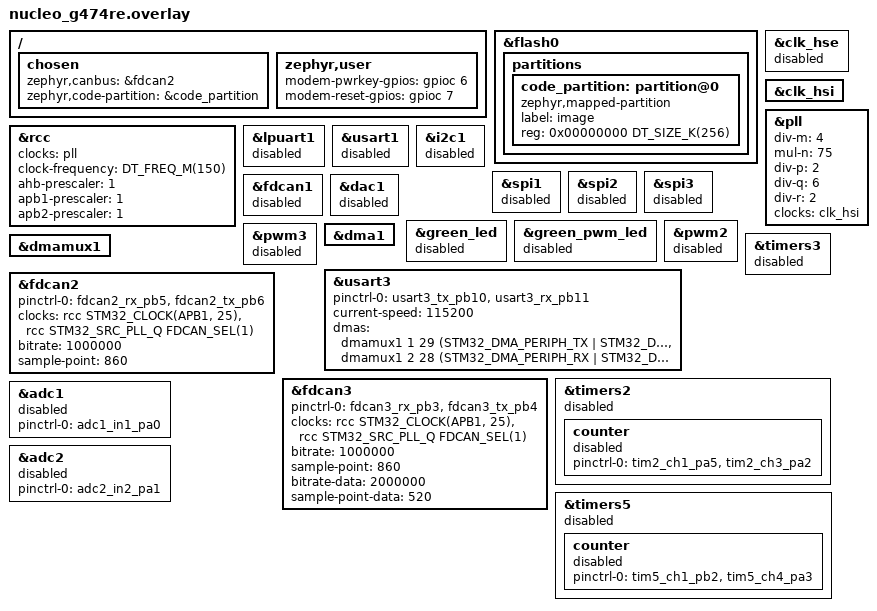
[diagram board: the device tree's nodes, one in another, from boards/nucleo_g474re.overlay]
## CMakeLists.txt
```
cmake_minimum_required(VERSION 3.20.0)

find_package(Zephyr REQUIRED HINTS $ENV{ZEPHYR_BASE})
project(telemetry27)

target_sources(app PRIVATE
	src/main.c
	src/platform.c
	src/telemetry.c
	src/telemetry_buffer.c
	src/telemetry_pack.c
	src/can_decode.c
	src/can_bus.c
	src/modem_fsm.c
	src/modem_at.c
	src/modem_parser.c
	src/modem_uart.c
	src/modem_power.c
)

target_sources_ifdef(CONFIG_TELEMETRY_SIM app PRIVATE
	src/modem_port_sim.c
	src/sim_vehicle.c
)

target_sources_ifndef(CONFIG_TELEMETRY_SIM app PRIVATE
	src/modem_port_hw.c
)
```

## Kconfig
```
# SPDX-License-Identifier: Apache-2.0

mainmenu "Telemetry27"

menu "Telemetry application"

config TELEMETRY_SIM
	bool "Host simulation of CAN frames and Quectel AT replies"
	default y if BOARD_NATIVE_SIM || BOARD_QEMU_CORTEX_M3
	help
	  Build without STM32 peripherals. A thread injects BMS 0x060 and
	  inverter 0x0B0 frames, and the modem port answers AT commands
	  with OK, the QISEND prompt and SEND OK.

endmenu

source "Kconfig.zephyr"
```

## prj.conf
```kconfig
CONFIG_LOG=y
CONFIG_LOG_DEFAULT_LEVEL=3
CONFIG_REBOOT=y

# ring_buf her zaman derlenir. CONFIG_RING_BUFFER Zephyr 4.4'te eski
# claim/finish API'sini geri getiren, kaldirilacak bir anahtardir.
```

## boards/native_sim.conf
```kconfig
CONFIG_LOG_MODE_IMMEDIATE=y
```

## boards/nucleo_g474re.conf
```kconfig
CONFIG_USE_DT_CODE_PARTITION=y

CONFIG_UART_CONSOLE=n
CONFIG_USE_SEGGER_RTT=y
CONFIG_RTT_CONSOLE=y
CONFIG_LOG_BACKEND_RTT=y
CONFIG_LOG_BACKEND_RTT_MODE_DROP=y

CONFIG_GPIO=y
CONFIG_SERIAL=y
CONFIG_UART_INTERRUPT_DRIVEN=y
CONFIG_UART_ASYNC_API=y

CONFIG_CAN=y
CONFIG_CAN_FD_MODE=y
CONFIG_CAN_DEFAULT_BITRATE=1000000
CONFIG_CAN_DEFAULT_BITRATE_DATA=2000000
```

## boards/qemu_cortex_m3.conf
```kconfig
CONFIG_TELEMETRY_SIM=y
CONFIG_LOG_MODE_IMMEDIATE=y
CONFIG_QEMU_EXTRA_FLAGS="-semihosting"
```

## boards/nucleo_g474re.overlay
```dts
/*
 * Telemetry27 pin haritasi.
 *
 * Derleme hedefi nucleo_g474re: Zephyr'de hazir olan en yakin kart.
 * Asil MCU STM32G474RCT6 (256 KB flash). Nucleo'daki G474RET6 512 KB'dir.
 * Asagidaki kod bolumu 256 KB'a sabitlenir ki imaj gercek karta da sigsin
 * ve 0x08000000'dan baslasin. Nucleo tanimi aksi halde uygulamayi MCUboot
 * slotuna (0x0800C000) yerlestirir; bootloader olmadan islemci oradan acilmaz.
 *
 * Saat, calisan Cube firmware ile ayni: HSI 16 MHz / 4 * 75, PLLR /2 = 150 MHz.
 * FDCAN cekirdegi PLLQ /6 = 50 MHz. .ioc PF0/PF1'i HSE gosterir; SystemClock_Config
 * HSE'yi acmaz. Nucleo'nun 24 MHz HSE'si bu kartta yok, o yuzden kapali.
 */

#include <zephyr/dt-bindings/dma/stm32_dma.h>

/ {
	chosen {
		zephyr,canbus = &fdcan2;
		zephyr,code-partition = &code_partition;
	};

	zephyr,user {
		modem-pwrkey-gpios = <&gpioc 6 GPIO_ACTIVE_HIGH>;
		modem-reset-gpios = <&gpioc 7 GPIO_ACTIVE_HIGH>;
	};
};

/delete-node/ &boot_partition;
/delete-node/ &slot0_partition;
/delete-node/ &slot1_partition;
/delete-node/ &storage_partition;

&flash0 {
	partitions {
		code_partition: partition@0 {
			compatible = "zephyr,mapped-partition";
			label = "image";
			reg = <0x00000000 DT_SIZE_K(256)>;
		};
	};
};

&clk_hse {
	status = "disabled";
};

&clk_hsi {
	status = "okay";
};

&pll {
	div-m = <4>;
	mul-n = <75>;
	div-p = <2>;
	div-q = <6>;
	div-r = <2>;
	clocks = <&clk_hsi>;
	status = "okay";
};

&rcc {
	clocks = <&pll>;
	clock-frequency = <DT_FREQ_M(150)>;
	ahb-prescaler = <1>;
	apb1-prescaler = <1>;
	apb2-prescaler = <1>;
};

/* Nucleo varsayilanlari bizim pinleri kaplar. Hepsini birakiyoruz. */
&lpuart1 {
	status = "disabled"; /* PA2, PA3: TIM, ST-Link konsolu degil */
};

&usart1 {
	status = "disabled";
};

&i2c1 {
	status = "disabled";
};

&spi1 {
	status = "disabled"; /* PA5: tekerlek TIM2_CH1, Nucleo LED/SPI degil */
};

&spi2 {
	status = "disabled";
};

&spi3 {
	status = "disabled";
};

&fdcan1 {
	status = "disabled"; /* PA11/PA12 bu kartta USB, CAN1 degil */
};

&dac1 {
	status = "disabled";
};

&green_led {
	status = "disabled"; /* PA5 */
};

&green_pwm_led {
	status = "disabled";
};

&pwm2 {
	status = "disabled"; /* tim2_ch1_pa5 */
};

&pwm3 {
	status = "disabled"; /* tim3_ch1_pb4 = bizim FDCAN3_TX */
};

&timers3 {
	status = "disabled";
};

/*
 * USART3, Quectel AT portu. PB10 TX, PB11 RX, 115200 8N1.
 * DMA kanallari Cube ile ayni: Channel1 TX (istek 29), Channel2 RX (istek 28).
 * Zephyr G4'te kanal numarasi 1'den baslar. RX dairesel; TX normal.
 */
&dma1 {
	status = "okay";
};

&dmamux1 {
	status = "okay";
};

&usart3 {
	pinctrl-0 = <&usart3_tx_pb10 &usart3_rx_pb11>;
	pinctrl-names = "default";
	current-speed = <115200>;
	dmas = <&dmamux1 1 29 (STM32_DMA_PERIPH_TX | STM32_DMA_PRIORITY_LOW)>,
	       <&dmamux1 2 28 (STM32_DMA_PERIPH_RX | STM32_DMA_PRIORITY_HIGH |
			       STM32_DMA_MODE_CYCLIC)>;
	dma-names = "tx", "rx";
	status = "okay";
};

/*
 * FDCAN saat kaynagi PLLQ (FDCAN_SEL 1). 50 MHz, prescaler 1.
 * Klasik 1 Mbit: 1+42+7 tq, ornek noktasi 860/1000.
 * FD data 2 Mbit: 1+12+12 tq, ornek noktasi 520/1000.
 * Zephyr seg1/seg2'yi bu ornek noktasindan kendisi secer.
 */
&fdcan2 {
	pinctrl-0 = <&fdcan2_rx_pb5 &fdcan2_tx_pb6>;
	pinctrl-names = "default";
	clocks = <&rcc STM32_CLOCK(APB1, 25)>,
		 <&rcc STM32_SRC_PLL_Q FDCAN_SEL(1)>;
	bitrate = <1000000>;
	sample-point = <860>;
	status = "okay";
};

&fdcan3 {
	pinctrl-0 = <&fdcan3_rx_pb3 &fdcan3_tx_pb4>;
	pinctrl-names = "default";
	clocks = <&rcc STM32_CLOCK(APB1, 25)>,
		 <&rcc STM32_SRC_PLL_Q FDCAN_SEL(1)>;
	bitrate = <1000000>;
	sample-point = <860>;
	bitrate-data = <2000000>;
	sample-point-data = <520>;
	status = "okay";
};

/* Tekerlek input-capture. Uygulama henuz okumuyor; pinler kayitli, surucu kapali. */
&timers2 {
	status = "disabled";

	counter {
		pinctrl-0 = <&tim2_ch1_pa5 &tim2_ch3_pa2>;
		pinctrl-names = "default";
		status = "disabled";
	};
};

&timers5 {
	status = "disabled";

	counter {
		pinctrl-0 = <&tim5_ch1_pb2 &tim5_ch4_pa3>;
		pinctrl-names = "default";
		status = "disabled";
	};
};

/*
 * ADC1 PA0 ve ADC2 PA1 Cube'da acik, App/ okumuyor.
 * Zephyr G4 dtsi su an iki ADC'yi ayni anda desteklemiyor; ikisi de kapali.
 */
&adc1 {
	pinctrl-0 = <&adc1_in1_pa0>;
	pinctrl-names = "default";
	status = "disabled";
};

&adc2 {
	pinctrl-0 = <&adc2_in2_pa1>;
	pinctrl-names = "default";
	status = "disabled";
};
```

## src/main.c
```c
#include <zephyr/kernel.h>
#include <zephyr/logging/log.h>

LOG_MODULE_REGISTER(app, LOG_LEVEL_INF);

int main(void)
{
	LOG_INF("Telemetry27 Zephyr");
#if IS_ENABLED(CONFIG_TELEMETRY_SIM)
	LOG_INF("endurance sim: 30 dk, 18000 paket");
#else
	LOG_INF("hedef STM32G474, USART3 / FDCAN2 / FDCAN3");
#endif
	return 0;
}
```

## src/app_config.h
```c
#ifndef APP_CONFIG_H_
#define APP_CONFIG_H_

/* Network */
#define APP_UDP_HOST              "135.125.196.63"
#define APP_UDP_PORT              5010
#define APP_APN                   "internet"

/* Pack rate: 10 Hz for vehicle/site trial; flip APP_TELEMETRY_10HZ to 0
 * for the proven 2 Hz (500 ms) TX-safe bench/vehicle fallback. */
#define APP_TELEMETRY_10HZ            1
#if APP_TELEMETRY_10HZ
#define APP_TELEMETRY_PERIOD_MS       100u   /* 10 Hz — Final26 vehicle rate */
#else
#define APP_TELEMETRY_PERIOD_MS       500u   /* 2 Hz — shared-rail / weak PSU */
#endif

/* Modem boot delay before GSM task starts link bring-up */
#define APP_GSM_BOOT_DELAY_MS     3000u

/* Warm flash: 0 = Final26 (AT OK → leave modem on, no QPOWD). 1 = force soft power-down. */
#define APP_MODEM_WARM_FLASH_QPOWD    0

/* RF: off = Quectel default (~23 dBm). Set 1 + 1800 for shared-+5V bench. */
#define APP_MODEM_RF_PROFILE_ENABLE   0
#define APP_MODEM_SARCFG_MAX_POWER    1800u   /* 18.0 dBm when profile on */
#define APP_MODEM_SARCFG_BAND         20u

/* Feature flags */
#define APP_TELEMETRY_LOW_BW_ENABLE   0
/* 0 = vehicle: MainBuffer filled only from CAN decode (no mock overwrite). */
#define APP_TELEMETRY_BENCH_TEST      0
#define APP_MODEM_DEBUG_LOG           1

/* Watchdog / recovery */
#define APP_GSM_SILENCE_WATCHDOG      1
#define APP_GSM_SILENCE_RESET_MS      120000u

#define APP_IWDG_ENABLE_REFRESH       1

#endif /* APP_CONFIG_H_ */
```

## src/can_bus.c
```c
#include "can_bus.h"
#include "can_decode.h"
#include "telemetry_buffer.h"

#include <string.h>
#include <zephyr/kernel.h>
#include <zephyr/logging/log.h>

LOG_MODULE_REGISTER(can_bus, LOG_LEVEL_INF);

struct can_rx_msg {
	uint8_t bus;
	uint8_t len;
	uint16_t pad;
	uint32_t id;
	uint8_t data[64];
};

K_MSGQ_DEFINE(can_rx_q, sizeof(struct can_rx_msg), 24, 4);

void can_rx_submit(uint8_t bus, uint32_t id, const uint8_t *data, uint8_t len)
{
	struct can_rx_msg msg;

	memset(&msg, 0, sizeof(msg));
	msg.bus = bus;
	msg.id = id;
	msg.len = len > sizeof(msg.data) ? (uint8_t)sizeof(msg.data) : len;
	if (data != NULL && msg.len > 0u) {
		memcpy(msg.data, data, msg.len);
	}
	if (k_msgq_put(&can_rx_q, &msg, K_NO_WAIT) != 0) {
		evt_overflow_cnt++;
	}
}

#if !IS_ENABLED(CONFIG_TELEMETRY_SIM)

#include <zephyr/device.h>
#include <zephyr/drivers/can.h>

static const struct device *const can_classic = DEVICE_DT_GET(DT_NODELABEL(fdcan2));
static const struct device *const can_fd = DEVICE_DT_GET(DT_NODELABEL(fdcan3));

static void can_rx_cb(const struct device *dev, struct can_frame *frame, void *user)
{
	uint8_t len;

	ARG_UNUSED(dev);
	len = can_dlc_to_bytes(frame->dlc);
	can_rx_submit((uint8_t)(uintptr_t)user, frame->id, frame->data, len);
}

static int add_accept_all(const struct device *dev, uintptr_t bus)
{
	const struct can_filter std = {
		.id = 0u,
		.mask = 0u,
		.flags = 0u,
	};
	const struct can_filter ext = {
		.id = 0u,
		.mask = 0u,
		.flags = CAN_FILTER_IDE,
	};
	int id;

	id = can_add_rx_filter(dev, can_rx_cb, (void *)bus, &std);
	if (id < 0) {
		LOG_ERR("std filtre %d", id);
		return id;
	}
	id = can_add_rx_filter(dev, can_rx_cb, (void *)bus, &ext);
	if (id < 0) {
		LOG_WRN("ext filtre %d", id);
	}
	return 0;
}

static int start_controller(const struct device *dev, uintptr_t bus, const char *name)
{
	int rc;

	if (!device_is_ready(dev)) {
		LOG_ERR("%s hazir degil", name);
		return -1;
	}
	rc = add_accept_all(dev, bus);
	if (rc != 0) {
		return rc;
	}
	rc = can_start(dev);
	if (rc != 0) {
		LOG_ERR("%s start %d", name, rc);
		return rc;
	}
	LOG_INF("%s dinleniyor", name);
	return 0;
}

static void can_hw_start(void)
{
	(void)start_controller(can_classic, CAN_BUS_CLASSIC, "fdcan2");
	(void)start_controller(can_fd, CAN_BUS_FD, "fdcan3");
}

#else

static void can_hw_start(void)
{
	LOG_INF("CAN donanimi yok, cerceveler sim_vehicle'dan gelecek");
}

#endif

static void can_thread(void *p1, void *p2, void *p3)
{
	ARG_UNUSED(p1);
	ARG_UNUSED(p2);
	ARG_UNUSED(p3);

	can_hw_start();
	while (1) {
		struct can_rx_msg msg;

		if (k_msgq_get(&can_rx_q, &msg, K_FOREVER) != 0) {
			continue;
		}
		telemetry_lock();
		CAN_ProcessRxFrame(msg.bus, msg.id, msg.data, msg.len);
		telemetry_on_can_id(msg.id);
		telemetry_unlock();
	}
}

K_THREAD_DEFINE(can_tid, 2048, can_thread, NULL, NULL, NULL, 4, 0, 0);
```

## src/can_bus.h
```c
#ifndef CAN_BUS_H_
#define CAN_BUS_H_

#include <stdint.h>

void can_rx_submit(uint8_t bus, uint32_t id, const uint8_t *data, uint8_t len);

#endif
```

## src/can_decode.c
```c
/*
 * can_decode.c
 *
 *  Created on: 18 Tem 2026
 *      Author: onury
 */

/*
 * Faz 3: CAN -> MainBuffer decode. Tek giris fonksiyonu (CAN_ProcessRxFrame)
 * her cerceveyi bus + ID'ye gore cozer ve fiziksel degerleri MainBuffer'a yazar.
 *
 * Referans: vcu26_firmware/CM7 decode kodlari (bms.cpp, lvbms.cpp, imu.cpp,
 * GPS.cpp, damper.cpp, brake.cpp, dashboard.cpp, inverter.cpp) ve can_decode.h.
 * Olcek/endianness/bayt-offset degerleri VCU decode ile birebir aynidir.
 *
 * NOT (birim): Telemetry_TransmitFrame her alani kendi olcegiyle paketler
 * (or. f[...]*100 -> i16). Bu yuzden burada FIZIKSEL deger yazilir; VCU'nun
 * ayni fiziksel degeri urettigi dogrulandi. Tek istisna damper: VCU metre
 * uretir ama telemetri paketlemesi *10 oldugundan burada mm saklanir (asagida).
 */

#include "can_decode.h"
#include "telemetry_buffer.h"
#include <string.h>

extern MainBuffer_t MainBuffer;

static uint16_t damper_raw_fl = (uint16_t)DAMPER_REST_FL;
static uint16_t damper_raw_fr = (uint16_t)DAMPER_REST_FR;
static uint16_t damper_raw_rl = (uint16_t)DAMPER_REST_RL;
static uint16_t damper_raw_rr = (uint16_t)DAMPER_REST_RR;

static int16_t inv_dcbus_voltage_scaled = 0; /* V (int16, /10 uygulanmis) */
/* 0x060 geldi → hücre temp/volt delta referansı (min) geçerli (VCU/dash birebir). */
static uint8_t bms_cell_min_valid = 0;
/* 0x256 d4 araç hızı otoritesi (dashboard ile aynı). Yoksa 0x0B0 RPM fallback. */
static uint8_t vcu_speed_from_status = 0;

#define BMS_CELL_V_MIN  2.50f
#define BMS_CELL_V_MAX  4.25f

static uint8_t encode_temp_u8(float temp_c)
{
    float enc = temp_c + 40.0f;
    if (enc < 0.0f)   enc = 0.0f;
    if (enc > 255.0f) enc = 255.0f;
    return (uint8_t)enc;
}

static void diff_checker(const uint8_t *d, uint8_t count)
{
    const float min_v = MainBuffer.f[BMS_MIN_CELL_VOLTAGE_f];
    if (min_v <= 0.0f) {
        return;
    }

    for (uint8_t i = 0; i < count; i++) {
        const float cell_v = min_v + ((float)d[i] / 100.0f);
        if (cell_v < BMS_CELL_V_MIN || cell_v > BMS_CELL_V_MAX) {
            Telemetry_SetError(ERR_BMS_CELL_VOLTAGE);
            return; /* baska bank OK diye temizleme — sticky */
        }
    }
}

int32_t CAN_DecodeRaw(const uint8_t *d, uint8_t start, uint8_t width, bool sgned, bool bigendian){
    uint32_t raw = 0;
    if (bigendian == true) {
        for (uint8_t i = 0; i < width; i++)
            raw = (raw << 8) | d[start + i];          /* d[start] = MSB */
    } else {
        for (uint8_t i = 0; i < width; i++)
            raw |= (uint32_t)d[start + i] << (8 * i);  /* d[start] = LSB */
    }
    if (sgned == true && width < 4){                            /* isaret genisletme */
        uint32_t signbit = 1u << (8 * width - 1);
        if (raw & signbit)
            raw |= ~((1u << (8 * width)) - 1);
    }
    return (int32_t)raw;
}

float CAN_Decode(const uint8_t *d, uint8_t start, uint8_t width, bool sgned, bool bigendian, float scale){
    int32_t raw = CAN_DecodeRaw(d, start, width, sgned, bigendian);
    return (scale != 0.0f) ? (float)raw / scale : (float)raw;
}

static float damper_angle_dev(uint16_t raw, float rest)
{
    float diff = (float)raw - rest;
    while (diff >  DAMPER_RAW_HALF) diff -= DAMPER_RAW_FULL;
    while (diff < -DAMPER_RAW_HALF) diff += DAMPER_RAW_FULL;
    return diff / DAMPER_RAW_PER_DEG;
}

static void damper_recompute(void)
{
    /* kose aci sapmasi (derece) * mirror isareti ("sikisma = +") */
    float devFL = damper_angle_dev(damper_raw_fl, DAMPER_REST_FL) * DAMPER_SIGN_FL;
    float devFR = damper_angle_dev(damper_raw_fr, DAMPER_REST_FR) * DAMPER_SIGN_FR;
    float devRL = damper_angle_dev(damper_raw_rl, DAMPER_REST_RL) * DAMPER_SIGN_RL;
    float devRR = damper_angle_dev(damper_raw_rr, DAMPER_REST_RR) * DAMPER_SIGN_RR;

    /* derece -> mm  (VCU: derece->metre; biz mm sakliyoruz ki TransmitFrame'in
     * *10 paketlemesi cozunurlugu korusun. Motion ratio VCU'da placeholder.) */
    const float k = DAMPER_M_PER_DEG * DAMPER_MM_PER_M; /* mm/derece */
    float zFL = devFL * k, zFR = devFR * k, zRL = devRL * k, zRR = devRR * k;

    /* heave = ortalama dusey hareket, roll = sol-sag farki / 2 (VCU modal ayrisim) */
    MainBuffer.f[DAMPER_COMPRESSION_FH_f] = (zFL + zFR) * 0.5f; /* on heave  (mm) */
    MainBuffer.f[DAMPER_COMPRESSION_FR_f] = (zFL - zFR) * 0.5f; /* on roll   (mm) */
    MainBuffer.f[DAMPER_COMPRESSION_RH_f] = (zRL + zRR) * 0.5f; /* arka heave(mm) */
    MainBuffer.f[DAMPER_COMPRESSION_RR_f] = (zRL - zRR) * 0.5f; /* arka roll (mm) */
    /* per-kose dusey hareket (mm) */
    MainBuffer.f[WHEEL_TRAVEL_FL_f] = zFL;
    MainBuffer.f[WHEEL_TRAVEL_FR_f] = zFR;
    MainBuffer.f[WHEEL_TRAVEL_RL_f] = zRL;
    MainBuffer.f[WHEEL_TRAVEL_RR_f] = zRR;
}

/* ======================= Tek decode/dispatch fonksiyonu ======================= */
void CAN_ProcessRxFrame(uint8_t bus, uint32_t id, const uint8_t *d, uint8_t len)
{
    /* ================= FD hatti (FDCAN3): BMS, LV-BMS, IMU, GPS ================= */
    if (bus == CAN_BUS_FD) {
        switch (id) {

        /* ---- HV BMS ozet (LE, >=30B) — Excel(7) / VCU bms.cpp / dash Decode_BMS_0x60 ---- */
        case CANID_BMS:
            if (len < 30u) break;
            MainBuffer.f[BMS_MAX_CELL_TEMP_f]    = CAN_Decode(d,  0, 2, true,  false, 100.0f);
            MainBuffer.f[BMS_MIN_CELL_TEMP_f]    = CAN_Decode(d,  2, 2, true,  false, 100.0f);
            MainBuffer.f[BMS_AVG_CELL_TEMP_f]    = CAN_Decode(d,  4, 2, true,  false, 100.0f);
            MainBuffer.f[BMS_MAX_SLAVE_TEMP_f]   = CAN_Decode(d,  6, 2, true,  false, 100.0f);
            MainBuffer.f[BMS_MAX_CELL_VOLTAGE_f] = CAN_Decode(d,  8, 2, false, false, 100.0f);
            MainBuffer.f[BMS_MIN_CELL_VOLTAGE_f] = CAN_Decode(d, 10, 2, false, false, 100.0f);
            /* d[12]=maxCellNo, d[13]=minCellNo -> telemetri'de alan yok, atla */
            MainBuffer.f[BMS_AVG_CELL_VOLTAGE_f] = CAN_Decode(d, 14, 2, false, false, 100.0f);
            MainBuffer.f[BMS_TOTAL_VOLTAGE_f]    = CAN_Decode(d, 16, 2, false, false, 100.0f);
            MainBuffer.f[BMS_ESTIMATED_SoC_f]    = CAN_Decode(d, 18, 2, false, false, 10000.0f);
            MainBuffer.u32[BMS_POWER_u32]        = (uint32_t)CAN_DecodeRaw(d, 20, 3, false, false);
            MainBuffer.f[BMS_CURRENT_f]          = CAN_Decode(d, 23, 2, true,  false, 10.0f);
            MainBuffer.u16[BMS_FAULTS_u16]       = (uint16_t)CAN_DecodeRaw(d, 25, 2, false, false);
            /* d[27..28]=leftChargeSec -> telemetri'de alan yok, atla */
            MainBuffer.u8[BMS_CONTRACTORS_u8]    = d[29];
            bms_cell_min_valid = 1u;
            break;

        /* ---- Hucre gerilimleri: her bayt MIN hucreye gore DELTA (ham byte saklanir) ----
         * Sunucu: hucre_V = BMS_MIN_CELL_VOLTAGE + delta/100. cell_voltages[] u8. */
        case CANID_BMS_VOLT1:
            if (!bms_cell_min_valid || len < 32u) break;
            memcpy(&MainBuffer.cell_voltages[0],  d, 32);
            diff_checker(d, 32);
            break;
        case CANID_BMS_VOLT2:
            if (!bms_cell_min_valid || len < 32u) break;
            memcpy(&MainBuffer.cell_voltages[32], d, 32);
            diff_checker(d, 32);
            break;
        case CANID_BMS_VOLT3:
            if (!bms_cell_min_valid || len < 32u) break;
            memcpy(&MainBuffer.cell_voltages[64], d, 32);
            diff_checker(d, 32);
            break;

        /* ---- Hucre sicakliklari: u16 LE delta /100; abs = MIN_CELL_TEMP + delta
         * (VCU bms.cpp + dash Decode_BMS_CellTemps). Paket: °C+40 → u8. ---- */
        case CANID_BMS_TEMP1:
            if (!bms_cell_min_valid || len < 64u) break;
            for (uint8_t i = 0; i < 32; i++) {
                float t = MainBuffer.f[BMS_MIN_CELL_TEMP_f] +
                          CAN_Decode(d, (uint8_t)(i * 2u), 2, false, false, 100.0f);
                MainBuffer.cell_temperatures[i] = encode_temp_u8(t);
            }
            break;

        case CANID_BMS_TEMP2:
            if (!bms_cell_min_valid || len < 64u) break;
            for (uint8_t i = 0; i < 32; i++) {
                float t = MainBuffer.f[BMS_MIN_CELL_TEMP_f] +
                          CAN_Decode(d, (uint8_t)(i * 2u), 2, false, false, 100.0f);
                MainBuffer.cell_temperatures[i + 32] = encode_temp_u8(t);
            }
            break;

        case CANID_BMS_TEMP3:
            if (!bms_cell_min_valid || len < 64u) break;
            for (uint8_t i = 0; i < 32; i++) {
                float t = MainBuffer.f[BMS_MIN_CELL_TEMP_f] +
                          CAN_Decode(d, (uint8_t)(i * 2u), 2, false, false, 100.0f);
                MainBuffer.cell_temperatures[i + 64] = encode_temp_u8(t);
            }
            break;

        /* ---- LV BMS (LE, >=23B) ---- */
        case CANID_LVBMS:
            if (len < 23u) break;
            MainBuffer.f[LVBMS_VOLTAGE_f]          = CAN_Decode(d,  0, 2, false, false, 100.0f);
            MainBuffer.f[LVBMS_CELL_REAL0_f]       = CAN_Decode(d,  2, 2, false, false, 100.0f);
            MainBuffer.f[LVBMS_CELL_REAL1_f]       = CAN_Decode(d,  4, 2, false, false, 100.0f);
            MainBuffer.f[LVBMS_CELL_REAL2_f]       = CAN_Decode(d,  6, 2, false, false, 100.0f);
            MainBuffer.f[LVBMS_CELL_REAL3_f]       = CAN_Decode(d,  8, 2, false, false, 100.0f);
            MainBuffer.f[LVBMS_MAX_CELL_VOLTAGE_f] = CAN_Decode(d, 10, 2, false, false, 100.0f);
            MainBuffer.f[LVBMS_MIN_CELL_VOLTAGE_f] = CAN_Decode(d, 12, 2, false, false, 100.0f);
            MainBuffer.u8[LVBMS_CELL_MIN_NUMBER_u8] = d[14];
            MainBuffer.u8[LVBMS_CELL_MAX_NUMBER_u8] = d[15];
            MainBuffer.f[LVBMS_CURRENT_f]          = CAN_Decode(d, 16, 2, true,  false, 10.0f);
            MainBuffer.f[LVBMS_MAX_TEMP_f]         = CAN_Decode(d, 18, 2, true,  false, 100.0f);
            MainBuffer.f[LVBMS_MIN_TEMP_f]         = CAN_Decode(d, 20, 2, true,  false, 100.0f);
            MainBuffer.u8[LVBMS_FAULTBYTE_u8]      = d[22];
            /* LVBMS_ESTIMATED_SoC: 0x131'de yok -> yazilmaz */
            break;

        /* ---- IMU 0x220 (LE): Excel(7) / VCU imu.cpp / dash Decode_IMU_0x220 ----
         * accel/gyro/euler + calib@24-27 + health@28-30; mag reserved=0;
         * quat@32-39 sadece DLC>=48. */
        case CANID_IMU:
            if (len < 28u) break; /* accel..calib icin minimum */
            MainBuffer.f[IMU_ACCEL_X_f]     = CAN_Decode(d,  0, 2, true, false, 100.0f);
            MainBuffer.f[IMU_ACCEL_Y_f]     = CAN_Decode(d,  2, 2, true, false, 100.0f);
            MainBuffer.f[IMU_ACCEL_Z_f]     = CAN_Decode(d,  4, 2, true, false, 100.0f);
            MainBuffer.f[IMU_GYRO_X_f]      = CAN_Decode(d,  6, 2, true, false, 16.0f);
            MainBuffer.f[IMU_GYRO_Y_f]      = CAN_Decode(d,  8, 2, true, false, 16.0f);
            MainBuffer.f[IMU_GYRO_Z_f]      = CAN_Decode(d, 10, 2, true, false, 16.0f);
            MainBuffer.f[YAW_RATE_f]        = MainBuffer.f[IMU_GYRO_Z_f]; /* gyroZ = yaw hizi */
            MainBuffer.f[IMU_EULER_YAW_f]   = CAN_Decode(d, 12, 2, true, false, 16.0f);
            MainBuffer.f[IMU_EULER_ROLL_f]  = CAN_Decode(d, 14, 2, true, false, 16.0f);
            MainBuffer.f[IMU_EULER_PITCH_f] = CAN_Decode(d, 16, 2, true, false, 16.0f);
            /* Mag bytes 18-23: imu26 artik basmiyor — stale birikmesin diye sifirla. */
            MainBuffer.f[IMU_MAG_X_f] = 0.0f;
            MainBuffer.f[IMU_MAG_Y_f] = 0.0f;
            MainBuffer.f[IMU_MAG_Z_f] = 0.0f;
            MainBuffer.u8[IMU_CALIB_SYS_u8]         = d[24];
            MainBuffer.u8[IMU_CALIB_GYRO_u8]        = d[25];
            MainBuffer.u8[IMU_CALIB_ACCEL_u8]       = d[26];
            MainBuffer.u8[IMU_CALIB_MAG_u8]         = d[27];
            /* Quat WXYZ @32-39 (DLC 48). Eski DLC32'de quat yok — onceki degeri koru. */
            if (len >= 48u) {
                MainBuffer.f[IMU_QUAT_W_f] = CAN_Decode(d, 32, 2, true, false, 16384.0f);
                MainBuffer.f[IMU_QUAT_X_f] = CAN_Decode(d, 34, 2, true, false, 16384.0f);
                MainBuffer.f[IMU_QUAT_Y_f] = CAN_Decode(d, 36, 2, true, false, 16384.0f);
                MainBuffer.f[IMU_QUAT_Z_f] = CAN_Decode(d, 38, 2, true, false, 16384.0f);
            }
            break;

        /* ---- VCU status 0x256 (LE, >=12B) — dash Decode_VCU_Status_0x256 ----
         * d[4] = vehicle speed otoritesi (dashboard ile ayni). */
        case CANID_VCU_STATUS:
            if (len < 12u) break;
            MainBuffer.u8[VCU_VEHICLE_STATE_u8] = d[0];
            MainBuffer.u8[VCU_DRIVE_MODE_u8]   = d[1];
            MainBuffer.u8[VCU_VEHICLE_SPEED_u8] = d[4];
            MainBuffer.u8[THROTTLE_PERCENT_u8]  = d[5];
            MainBuffer.u8[VCU_APP_STATE_REQ_u8] = d[6];
            MainBuffer.u16[VCU_TORQUE_NM_REQ_u16] =
                (uint16_t)(d[8] | ((uint16_t)d[9] << 8));
            MainBuffer.u8[TIRE_SPEED_RR_u8] = d[10];
            MainBuffer.u8[TIRE_SPEED_RL_u8] = d[11];
            vcu_speed_from_status = 1u;
            break;

        /* ---- GPS (BIG-ENDIAN, >=14B for lat/lon/speed) ---- */
        case CANID_GPS:
            if (len < 14u) break;
            MainBuffer.i32[GPS_LATITUDE_i32]   = CAN_DecodeRaw(d, 0, 4, true, true); /* ham (x1e-7) */
            MainBuffer.i32[GPS_LONGTITUDE_i32] = CAN_DecodeRaw(d, 4, 4, true, true);
            /* yer hizi: byte12-13 UNSIGNED BE, /100 -> km/h, u8'e sigdir */
            {
                float kmh = CAN_Decode(d, 12, 2, false, true, 100.0f);
                if (kmh < 0.0f)   kmh = 0.0f;
                if (kmh > 255.0f) kmh = 255.0f;
                MainBuffer.u8[GPS_SPEED_u8] = (uint8_t)kmh;
            }
            break;

        default:
            break;
        }
        return;
    }

    /* ================= Classic hatti (FDCAN2): Inverter, Damper, Fren, Dashboard ================= */
    if (bus == CAN_BUS_CLASSIC) {
        switch (id) {

        /* ---------------- Inverter (Cascadia tarzi, LE, 8B) ---------------- */
        case CANID_INV_HIGHSPEED: { /* 0x0B0 */
            if (len < 8u) break;
            MainBuffer.i16[INV_TORQUE_EST_NM_i16] = (int16_t)CAN_Decode(d, 2, 2, true, false, 10.0f);
            int32_t motor_speed = CAN_DecodeRaw(d, 4, 2, true, false);      /* ham RPM */
            MainBuffer.i32[INV_EMACHINE_SPEED_ERPM_i32] = motor_speed;
            /* Dashboard: araç hızı 0x256 d4. VCU status yoksa RPM→km/h fallback. */
            if (!vcu_speed_from_status) {
                int32_t v = (int32_t)((float)motor_speed * 0.02394f);
                if (v < 0)   v = 0;
                if (v > 255) v = 255;
                MainBuffer.u8[VCU_VEHICLE_SPEED_u8] = (uint8_t)v;
            }
            inv_dcbus_voltage_scaled = (int16_t)CAN_Decode(d, 6, 2, true, false, 10.0f);
            MainBuffer.u16[INV_DCBUS_VOLTAGE_u16] = (uint16_t)inv_dcbus_voltage_scaled;
            break;
        }
        case CANID_INV_TEMP1: { /* 0x0A0: faz sicakliklari + gate driver */
            if (len < 8u) break;
            int16_t pa = (int16_t)CAN_Decode(d, 0, 2, true, false, 10.0f);
            int16_t pb = (int16_t)CAN_Decode(d, 2, 2, true, false, 10.0f);
            int16_t pc = (int16_t)CAN_Decode(d, 4, 2, true, false, 10.0f);
            int16_t mx = pa; if (pb > mx) mx = pb; if (pc > mx) mx = pc;
            MainBuffer.i16[INV_PWRSTG_TEMP_i16]  = mx;                      /* max(faz A/B/C) */
            MainBuffer.i16[INV_BOARD_1_TEMP_i16] = (int16_t)CAN_Decode(d, 6, 2, true, false, 10.0f);
            break;
        }
        case CANID_INV_TEMP2: /* 0x0A1: kontrol karti sicakligi */
            if (len < 2u) break;
            MainBuffer.i16[INV_BOARD_2_TEMP_i16] = (int16_t)CAN_Decode(d, 0, 2, true, false, 10.0f);
            break;
        case CANID_INV_TEMP3: /* 0x0A2: motor sicakligi */
            if (len < 6u) break;
            MainBuffer.i16[INV_EMACHINE_TEMP_1_i16] = (int16_t)CAN_Decode(d, 4, 2, true, false, 10.0f);
            break;
        case CANID_INV_CURRENT: { /* 0x0A6: DC akim + AC guc */
            if (len < 8u) break;
            int16_t dc_current = (int16_t)CAN_Decode(d, 6, 2, true, false, 10.0f); /* A */
            /* AC guc = Idc * Vdc / 100 (kW*10). Vdc 0x0B0'den. (faz akimlari telemetri'de yok) */
            MainBuffer.i16[INV_ACBUS_POWER_i16] =
                (int16_t)(((int32_t)dc_current * inv_dcbus_voltage_scaled) / 100);
            break;
        }
        case CANID_INV_FLUX: /* 0x0A8: Id/Iq feedback */
            if (len < 8u) break;
            MainBuffer.f[INV_CURRENT_D_A_f] = CAN_Decode(d, 4, 2, true, false, 10.0f);
            MainBuffer.f[INV_CURRENT_Q_A_f] = CAN_Decode(d, 6, 2, true, false, 10.0f);
            break;
        case CANID_INV_STATES: /* 0x0AA: VSM/inverter durum + bayrak kelimesi */
            if (len < 8u) break;
            if (d[0] < 16) { /* VCU ile ayni gecerlilik kosulu */
                MainBuffer.u8[INV_APP_STATE_APP_u8]       = d[0]; /* VSM_State  */
                MainBuffer.u8[INV_EMCTRL_FOC_BITSTATE_u8] = d[2]; /* Inverter_State */
                uint16_t flags = (uint16_t)(d[7] & 0x7F);
                flags |= (uint16_t)(d[6] & 0x01)        << 7;  /* Enable      */
                flags |= (uint16_t)((d[6] >> 7) & 0x01) << 8;  /* Lockout     */
                flags |= (uint16_t)((d[6] >> 6) & 0x01) << 9;  /* Start_Mode  */
                flags |= (uint16_t)(d[4] & 0x01)        << 10; /* Run_Mode    */
                flags |= (uint16_t)(d[5] & 0x01)        << 11; /* Command_Mode*/
                MainBuffer.u16[INV_PWRSTG_BITSTATE_u16]   = flags;
            }
            break;
        case CANID_INV_FAULTS: /* 0x0AB: POST(b0-3) / Run(b4-7) hata kelimeleri - VCU ile birebir */
            if (len < 8u) break;
            MainBuffer.u32[INV_DEM1_u32] =
                (uint32_t)d[0] | ((uint32_t)d[1] << 8) | ((uint32_t)d[2] << 16) | ((uint32_t)d[3] << 24);
            MainBuffer.u32[INV_DEM2_u32] =
                (uint32_t)d[4] | ((uint32_t)d[5] << 8) | ((uint32_t)d[6] << 16) | ((uint32_t)d[7] << 24);
            break;

        /* ---------------- Damper (LE, byte0-1 ham aci u16) ---------------- */
        case CANID_DAMPER_FL:
            if (len < 2u) break;
            damper_raw_fl = (uint16_t)(d[0] | (d[1] << 8)); damper_recompute(); break;
        case CANID_DAMPER_FR:
            if (len < 2u) break;
            damper_raw_fr = (uint16_t)(d[0] | (d[1] << 8)); damper_recompute(); break;
        case CANID_DAMPER_RL:
            if (len < 2u) break;
            damper_raw_rl = (uint16_t)(d[0] | (d[1] << 8)); damper_recompute(); break;
        case CANID_DAMPER_RR:
            if (len < 2u) break;
            damper_raw_rr = (uint16_t)(d[0] | (d[1] << 8)); damper_recompute(); break;

        /* ---------------- Fren basinci (CANopen DS404, TPDO1) ---------------- */
        case CANID_BRAKE_FRONT: {
            if (len < 4u) break;
            uint32_t rawp = (uint32_t)CAN_DecodeRaw(d, 0, 4, true, false); /* int32 LE */
            float bar = (float)(int32_t)rawp * BRAKE_PRESSURE_CONST;
            if (bar < 0.0f)   bar = 0.0f;
            if (bar > 255.0f) bar = 255.0f;
            MainBuffer.u8[BRAKE_PRESSURE_FRONT_u8] = (uint8_t)bar;
            break;
        }
        case CANID_BRAKE_REAR: {
            if (len < 4u) break;
            uint32_t rawp = (uint32_t)CAN_DecodeRaw(d, 0, 4, true, false);
            float bar = (float)(int32_t)rawp * BRAKE_PRESSURE_CONST;
            if (bar < 0.0f)   bar = 0.0f;
            if (bar > 255.0f) bar = 255.0f;
            MainBuffer.u8[BRAKE_PRESSURE_REAR_u8] = (uint8_t)bar;
            break;
        }

        /* ---------------- Dashboard / gaz (0x210, LE) ---------------- */
        case CANID_DASHBOARD:
            if (len < 6u) break;
            MainBuffer.u16[POT1_U16] = (uint16_t)(d[0] | (d[1] << 8)); /* APPS1 ham ADC */
            MainBuffer.u16[POT2_U16] = (uint16_t)(d[2] | (d[3] << 8)); /* APPS2 ham ADC */
            MainBuffer.u8[TIRE_SPEED_FR_u8] = d[4];
            MainBuffer.u8[TIRE_SPEED_FL_u8] = d[5];
            /* d[6]=buttons -> telemetri'de yok */
            break;

        default:
            break;
        }
        return;
    }
}
```

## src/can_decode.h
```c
/*
 * can_decode.h
 *
 * Faz 3: CAN hattindan gelen ham cerceveleri cozup MainBuffer'a yazan tek
 * decode modulunun arayuzu.
 *
 * Kaynak: vcu26_firmware (CM7) decode kodu esas alinmistir. Cozum kurallari
 * VCU'nun Decode::canDecode(...) yardimcisiyla birebir aynidir; her cihazin
 * bayt duzeni/olcek/endianness'i VCU decode dosyalarindan cikarilmistir.
 *
 * Bus atamasi (VCU numaralandirmasi bizde ters):
 *   - Classic 1 Mbit  -> FDCAN2 : Inverter, Damper x4, Fren F/R, Dashboard(0x210), (TMS kapali)
 *   - CAN-FD 1M/2M    -> FDCAN3 : HV BMS, LV-BMS, IMU, GPS, (VCU-status placeholder)
 */

#ifndef INC_CAN_DECODE_H_
#define INC_CAN_DECODE_H_

#include <stdint.h>
#include <stdbool.h>

#define CAN_BUS_CLASSIC 2u
#define CAN_BUS_FD      3u

/* ======================= CAN mesaj ID'leri ======================= */
/* --- FD hatti (FDCAN3) --- */
#define CANID_BMS            0x060u   /* HV BMS ozet (32B)            */
#define CANID_BMS_VOLT1      0x100u   /* hucre 0-31   delta byte      */
#define CANID_BMS_VOLT2      0x110u   /* hucre 32-63  delta byte      */
#define CANID_BMS_VOLT3      0x120u   /* hucre 64-95  delta byte      */
/* Hucre sicakliklari (32 x i16 LE /100, 64B FD). BMS master ID'leri. */
#define CANID_BMS_TEMP1      0x130u   /* hucre 0-31   temp            */
#define CANID_BMS_TEMP2      0x140u   /* hucre 32-63  temp            */
#define CANID_BMS_TEMP3      0x150u   /* hucre 64-95  temp            */
#define CANID_LVBMS          0x131u   /* LV BMS (24B)                 */
#define CANID_IMU            0x220u   /* IMU DLC48: quat@32-39 (Excel7/VCU/dash) */
#define CANID_GPS            0x230u   /* GPS (32B, BIG-ENDIAN)        */
#define CANID_VCU_STATUS     0x256u   /* VCU → Dash/Telemetry MSG-1   */
#define CANID_VCU_DIAG       0x257u   /* VCU → Dash MSG-2 (diag)      */

/* --- Classic hatti (FDCAN2) --- */
#define CANID_INV_TEMP1      0x0A0u   /* faz sicakliklari + gate driver */
#define CANID_INV_TEMP2      0x0A1u   /* kontrol karti sicakligi        */
#define CANID_INV_TEMP3      0x0A2u   /* motor sicakligi                */
#define CANID_INV_CURRENT    0x0A6u   /* faz/DC akim                    */
#define CANID_INV_FLUX       0x0A8u   /* Id/Iq feedback                 */
#define CANID_INV_STATES     0x0AAu   /* VSM/inverter durum + bayrak    */
#define CANID_INV_FAULTS     0x0ABu   /* POST/Run hata kelimeleri       */
#define CANID_INV_HIGHSPEED  0x0B0u   /* torque/hiz/DC bus V (hizli)    */
#define CANID_DAMPER_FL      0x1F5u   /* Sol On   (front-left)          */
#define CANID_DAMPER_FR      0x1F4u   /* Sag On   (front-right)         */
#define CANID_DAMPER_RL      0x1F1u   /* Sol Arka (rear-left)           */
#define CANID_DAMPER_RR      0x1F2u   /* Sag Arka (rear-right)          */
#define CANID_BRAKE_FRONT    0x181u   /* CANopen node1 TPDO1            */
#define CANID_BRAKE_REAR     0x182u   /* CANopen node2 TPDO1            */
#define CANID_DASHBOARD      0x210u   /* APPS pot1/pot2 + on teker hizi */

/* ======================= Damper sabitleri (damper.h ile ayni) ======================= */
#define DAMPER_RAW_FULL      4096.0f
#define DAMPER_RAW_HALF      2048.0f
#define DAMPER_RAW_PER_DEG   (4095.0f / 360.0f)  /* 11.375 ham/derece */
#define DAMPER_M_PER_DEG     0.001f              /* motion ratio (VCU'da placeholder) */
#define DAMPER_MM_PER_M      1000.0f
#define DAMPER_SIGN_FL       (+1.0f)
#define DAMPER_SIGN_FR       (-1.0f)
#define DAMPER_SIGN_RL       (+1.0f)
#define DAMPER_SIGN_RR       (-1.0f)
/* Kalibrasyon modu KAPALI -> sabit rest referanslari (damper.h) */
#define DAMPER_REST_FL       1950.0f
#define DAMPER_REST_FR       1223.0f
#define DAMPER_REST_RL       3551.0f
#define DAMPER_REST_RR       2697.0f

/* ======================= Fren sabiti (CANopen DS404) ======================= */
#define BRAKE_PRESSURE_CONST (1.0f / 1000.0f)    /* ham int32 -> bar */

/* ======================= Cozum yardimcilari (VCU Decode:: ile ayni) ======================= */
/*
 * be=true  -> big-endian (d[start] = MSB)
 * be=false -> little-endian (d[start] = LSB)
 * sgn=true -> 2's complement isaret genisletme (width<4)
 * canDecode: fiziksel = ham / scale   (scale==0 -> ham deger dondurulur)
 */
int32_t CAN_DecodeRaw(const uint8_t *d, uint8_t start, uint8_t width, bool sgn, bool be);
float   CAN_Decode(const uint8_t *d, uint8_t start, uint8_t width, bool sgn, bool be, float scale);

/* ======================= Tek decode/dispatch fonksiyonu ======================= */
/*
 * CAN is parcacigi bu fonksiyonu cagirir. bus CAN_BUS_CLASSIC (FDCAN2) veya
 * CAN_BUS_FD (FDCAN3). len bayt cinsindendir. Paketleme Telemetry_TransmitFrame'dedir.
 */
void CAN_ProcessRxFrame(uint8_t bus, uint32_t id, const uint8_t *data, uint8_t len);

#endif /* INC_CAN_DECODE_H_ */
```

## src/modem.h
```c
#ifndef MODEM_H_
#define MODEM_H_

#include <stdint.h>
#include <stdbool.h>
#include "modem_live.h"

void Modem_Init(void);
void Modem_Poll(void);
void Modem_SimulationStop(void);
bool Modem_IsReady(void);
bool Modem_RequestUdpSend(const uint8_t *buf, uint16_t len);
modem_state_t Modem_GetState(void);
const modem_live_t *Modem_GetLive(void);

extern volatile uint32_t last_modem_rx_tick;
extern volatile uint32_t modem_dma_restart_err_cnt;
extern uint8_t recovery_count;

#endif
```

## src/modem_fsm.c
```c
#include "modem.h"
#include "modem_internal.h"
#include <stdlib.h>
#include <zephyr/logging/log.h>

LOG_MODULE_REGISTER(modem_fsm, LOG_LEVEL_INF);

void Modem_SimulationStop(void)
{
#if defined(CONFIG_ARCH_POSIX)
	exit(0);
#elif defined(CONFIG_QEMU_TARGET)
	/* QEMU semihosting SYS_EXIT / ADP_Stopped_ApplicationExit */
	register unsigned int cmd __asm__("r0") = 0x18;
	register unsigned int arg __asm__("r1") = 0x20026;

	__asm__ volatile("bkpt 0xAB" : : "r"(cmd), "r"(arg) : "memory");
#else
	k_sleep(K_FOREVER);
#endif
}

volatile modem_live_t modem_live;
volatile uint32_t last_modem_rx_tick;
volatile uint8_t modem_net_lost;
volatile uint8_t modem_rf_collapse;

static modem_fsm_state_t fsm_state;
static uint8_t send_pending;
uint8_t recovery_count;
static uint8_t send_retry_count;
static uint8_t qiopen_fail_count;
static uint32_t last_send_tick;
static uint32_t send_backoff_ms;

void Modem_InitPowerPins(void);
void Modem_HwReset(void);
void Modem_SetPendingPayload(const uint8_t *buf, uint16_t len);
uint8_t Modem_IsUartBusy(void);

void Modem_UpdateLive(void)
{
    modem_live.send_pending = send_pending;
    modem_live.send_retry_count = send_retry_count;
    modem_live.send_backoff_ms = (uint16_t)send_backoff_ms;
    modem_live.fsm = (modem_live_fsm_t)fsm_state;
    modem_live.rx_fill = (uint16_t)ring_buf_size_get(&modem_rx_ring);
    modem_live.rx_dma_circular = 1u;
    modem_live.uart_rx_busy = 1u;
}

void Modem_Init(void)
{
    memset((void *)&modem_live, 0, sizeof(modem_live));
    modem_live.csq = -1; /* unset — not "99" until AT+CSQ says so */
    modem_live.cereg = -1;
    modem_live.cfun = -1;
    modem_live.airplane_ctl = -1;
    modem_live.airplane_status = -1;
    fsm_state = MODEM_FSM_INIT_AT;
    send_pending = 0;
    recovery_count = 0;
    send_retry_count = 0;
    qiopen_fail_count = 0;
    last_send_tick = 0;
    send_backoff_ms = 0;
    modem_net_lost = 0;
    modem_rf_collapse = 0;
    last_modem_rx_tick = platform_tick_ms();

    if (modem_port_init() != 0) {
        LOG_ERR("modem portu acilmadi");
    }
    Modem_InitPowerPins();
    k_msleep(100);
    Modem_UartBringup();

    /* Final26 GSM_Init — warm flash (PSU on): AT OK → DO NOT QPOWD/PWRKEY.
     * Mandatory QPOWD was leaving cfun=1 cpin_ok=1 but csq=99 / cereg=0 forever. */
    modem_live.state = MODEM_STATE_BOOTING;
#if APP_MODEM_WARM_FLASH_QPOWD
    Modem_EnsurePoweredDown();
    Modem_UartBringup();
    if (!Modem_ProbeOn()) {
        if (!Modem_PowerOnVerified()) {
            uint8_t filler[64];
            memset(filler, 'U', sizeof(filler));
            for (int k = 0; k < 8; k++) {
                (void)modem_port_write(filler, sizeof(filler));
            }
            (void)modem_port_write((const uint8_t *)"\r\n", 2);
            k_msleep(1000);
            (void)Modem_PowerOnVerified();
        }
    }
#else
    if (!Modem_ProbeOn()) {
        uint8_t filler[64];
        memset(filler, 'U', sizeof(filler));
        for (int k = 0; k < 8; k++) {
            (void)modem_port_write(filler, sizeof(filler));
        }
        (void)modem_port_write((const uint8_t *)"\r\n", 2);
        k_msleep(1000);
        if (!Modem_ProbeOn()) {
            (void)Modem_PowerOnVerified();
        }
    } else {
        modem_live.warm_skip_qpowd = 1;
    }
#endif
    (void)modem_port_write((const uint8_t *)"AT\r\n", 4);
    Modem_UartBringup();
    modem_live.state = MODEM_STATE_BOOTING;
}

bool Modem_RequestUdpSend(const uint8_t *buf, uint16_t len)
{
    if (!buf || len == 0 || len > TELEMETRY_BUFFER_LENGTH) return false;
    Modem_SetPendingPayload(buf, len);
    send_pending = 1;
    return true;
}

bool Modem_IsReady(void)
{
    return modem_live.ready != 0;
}

modem_state_t Modem_GetState(void)
{
    return modem_live.state;
}

const modem_live_t *Modem_GetLive(void)
{
    return (const modem_live_t *)&modem_live;
}

static uint8_t rf_good_live(void)
{
    return (uint8_t)(modem_live.csq >= 10 && modem_live.csq <= 31);
}

static uint8_t net_up_live(void)
{
    return (uint8_t)((modem_live.cereg == 1 || modem_live.cereg == 5) &&
                     modem_live.pdp_active);
}

void Modem_Poll(void)
{
    static modem_fsm_state_t logged = MODEM_FSM_HW_RESET;
    static const char *const name[] = {
        "HW_RESET", "INIT_AT", "CHECK_NET", "IDLE", "RECOVERY"
    };

    if (fsm_state != logged && fsm_state <= MODEM_FSM_RECOVERY_WAIT) {
        LOG_INF("durum %s", name[fsm_state]);
        logged = fsm_state;
    }

    Modem_RxPump();
    Modem_UpdateLive();
    Modem_ParseResponses();

    switch (fsm_state) {
    case MODEM_FSM_HW_RESET:
        modem_live.state = MODEM_STATE_RECOVERING;
        modem_live.ready = 0;
        Modem_HwReset(); /* already soft-rearms USART3 RX DMA */
        fsm_state = MODEM_FSM_INIT_AT;
        break;

    case MODEM_FSM_INIT_AT:
        modem_live.state = MODEM_STATE_BOOTING;
        if (Modem_InitModemConfig()) {
            fsm_state = MODEM_FSM_CHECK_NET;
        } else {
            if (recovery_count++ >= MODEM_MAX_RECOVERY) {
                recovery_count = 0;
                fsm_state = MODEM_FSM_HW_RESET;
            } else {
                fsm_state = MODEM_FSM_RECOVERY_WAIT;
            }
        }
        break;

    case MODEM_FSM_CHECK_NET:
        modem_live.state = MODEM_STATE_LINKING;
        modem_live.ready = 0;
        if (!Modem_ProbeOn()) {
            if (Modem_PowerOnVerified()) {
                fsm_state = MODEM_FSM_INIT_AT;
            } else {
                fsm_state = MODEM_FSM_HW_RESET;
            }
            break;
        }
        if (net_up_live()) {
            /* Şebeke + PDP ayakta: QICSGP/QIACT/CEREG tekrar etme — sadece soket (Final26). */
            if (Modem_EnsureSocketUp()) {
                recovery_count = 0;
                qiopen_fail_count = 0;
                fsm_state = MODEM_FSM_IDLE;
            } else {
                modem_live.recovery_count++;
                k_msleep(2000u);
            }
        } else if (Modem_BringLinkUp()) {
            recovery_count = 0;
            qiopen_fail_count = 0;
            fsm_state = MODEM_FSM_IDLE;
        } else if (!rf_good_live() && ++qiopen_fail_count >= 20u) {
            /* RESET_N cannot create coverage, so bad RF is the weakest possible
             * reason to pulse it — CHECK_NET already hard-resets when AT dies.
             * Kept only as a very-last-resort unwedge after ~30 min of no service. */
            qiopen_fail_count = 0;
            fsm_state = MODEM_FSM_HW_RESET;
        } else {
            modem_live.recovery_count++;
            k_msleep(rf_good_live() ? 500u : 5000u);
        }
        break;

    case MODEM_FSM_IDLE:
        /* Final26: CEREG drop → leave IDLE before burning QISEND ladder. */
        if (modem_net_lost) {
            modem_net_lost = 0;
            modem_live.ready = 0;
            modem_live.socket_open = 0;
            modem_live.state = MODEM_STATE_LINKING;
            fsm_state = MODEM_FSM_CHECK_NET;
            break;
        }
        /* Soket düştü ama şebeke ayakta: soft reopen (Final26 send-fail path). */
        if (!modem_live.socket_open) {
            modem_live.ready = 0;
            modem_live.state = MODEM_STATE_RECOVERING;
            if (!Modem_EnsureSocketUp()) {
                modem_live.state = MODEM_STATE_LINKING;
                fsm_state = MODEM_FSM_CHECK_NET;
                break;
            }
            modem_live.socket_open = 1;
        }
        modem_live.ready = 1;
        modem_live.state = MODEM_STATE_READY;

        if (send_pending && !Modem_IsUartBusy()) {
            uint32_t now = platform_tick_ms();
            if (last_send_tick != 0 &&
                (now - last_send_tick) < (MODEM_SEND_PACE_MS + send_backoff_ms)) {
                break;
            }
            last_send_tick = now;
            send_pending = 0;
            modem_live.ready = 0;
            modem_live.state = MODEM_STATE_SENDING;

            if (Modem_UdpSendNow()) {
                modem_live.qisend_ok++;
                LOG_DBG("QISEND ok #%u len=%u cereg=%d csq=%d",
                        modem_live.qisend_ok, modem_live.last_send_len,
                        modem_live.cereg, modem_live.csq);
                send_retry_count = 0;
                send_backoff_ms = 0;
                recovery_count = 0;
                modem_live.ready = 1;
                modem_live.state = MODEM_STATE_READY;
                break;
            }

            /* Final26 IDLE fail: EnsureCommandMode, same-socket retry.
             * Reopen only when QISTATE says down — never ForceRxArm thrash. */
            modem_live.qisend_fail++;
            send_pending = 1;
            last_send_tick = 0;
            Modem_EnsureCommandMode();
            if (send_retry_count < 255u) {
                send_retry_count++;
            }
            send_backoff_ms = 0;
            if (send_retry_count >= MODEM_SEND_RETRY_MAX) {
                send_retry_count = 0;
                if (!Modem_QuerySocketUp()) {
                    if (!Modem_SyncReopenSocket()) {
                        modem_live.ready = 0;
                        modem_live.socket_open = 0;
                        modem_live.state = MODEM_STATE_LINKING;
                        fsm_state = MODEM_FSM_CHECK_NET;
                        break;
                    }
                    modem_live.socket_open = 1;
                }
            }
            modem_live.ready = 1;
            modem_live.state = MODEM_STATE_READY;
        }
        break;

    case MODEM_FSM_RECOVERY_WAIT:
        /* INIT_AT failed — retry config, do not leap into CHECK_NET with
         * cpin/csq/cfun still unset (looks like "linking" while AT is dead). */
        modem_live.state = MODEM_STATE_RECOVERING;
        modem_live.recovery_count++;
        k_msleep(1000u << (recovery_count > 4 ? 4 : recovery_count));
        fsm_state = MODEM_FSM_INIT_AT;
        break;

    default:
        fsm_state = MODEM_FSM_INIT_AT;
        break;
    }
}

#if IS_ENABLED(CONFIG_TELEMETRY_SIM)
#define MODEM_THREAD_DELAY_MS 300
#else
#define MODEM_THREAD_DELAY_MS APP_GSM_BOOT_DELAY_MS
#endif

#define MODEM_STACK_SIZE 4096
#define MODEM_PRIORITY   7

static void modem_thread(void *p1, void *p2, void *p3)
{
	ARG_UNUSED(p1);
	ARG_UNUSED(p2);
	ARG_UNUSED(p3);

	Modem_Init();
	LOG_INF("modem thread hazir, poll 1 ms");
	while (1) {
		uint32_t now = platform_tick_ms();

		platform_watchdog_kick();
#if APP_GSM_SILENCE_WATCHDOG
		if ((now - last_modem_rx_tick) > APP_GSM_SILENCE_RESET_MS) {
			LOG_ERR("GSM sessizligi, reset");
			platform_reboot();
		}
#endif
		Modem_Poll();
		k_msleep(1);
	}
}

K_THREAD_DEFINE(modem_tid, MODEM_STACK_SIZE, modem_thread,
		NULL, NULL, NULL, MODEM_PRIORITY, 0, MODEM_THREAD_DELAY_MS);
```

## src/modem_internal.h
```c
#ifndef MODEM_INTERNAL_H_
#define MODEM_INTERNAL_H_

#include "modem.h"
#include "app_config.h"
#include "telemetry_buffer.h"
#include "platform.h"
#include "modem_port.h"

#include <string.h>
#include <stdio.h>
#include <zephyr/kernel.h>
#include <zephyr/sys/ring_buffer.h>

#define MODEM_RING_SIZE           1024u
#define MODEM_LINE_SIZE           256u
#define MODEM_AT_BUF_SIZE         256u
#define MODEM_EVT_QUEUE_SIZE      64u
#define MODEM_UDP_CMD_SIZE        64u

#define MODEM_MAX_RECOVERY        6u
#define MODEM_SEND_RETRY_MAX      3u
#define MODEM_SEND_PACE_MS        100u
#define MODEM_QIOPEN_SETTLE_MS    0u

#define MODEM_INIT_AT_MS          3000u
#define MODEM_PROMPT_TIMEOUT_MS   1000u
#define MODEM_QISEND_OK_MS        1200u
#define MODEM_QIOPEN_WAIT_MS      10000u
#define MODEM_QICLOSE_WAIT_MS     2000u
#define MODEM_CEREG_POLL_MS       2000u
#define MODEM_CEREG_GIVEUP_MS     90000u
#define MODEM_UE_RESET_GAP_MS     300000u
#define MODEM_PROBE_MS            1500u
#define MODEM_QPOWD_WAIT_MS       8000u

typedef enum {
	MODEM_EVT_NONE = 0,
	MODEM_EVT_OK,
	MODEM_EVT_ERROR,
	MODEM_EVT_PROMPT,
	MODEM_EVT_SIM_READY,
	MODEM_EVT_NET_READY,
	MODEM_EVT_UDP_SEND_OK,
	MODEM_EVT_UDP_OPEN_OK,
	MODEM_EVT_UART_ERROR
} modem_event_t;

typedef enum {
	MODEM_FSM_HW_RESET,
	MODEM_FSM_INIT_AT,
	MODEM_FSM_CHECK_NET,
	MODEM_FSM_IDLE,
	MODEM_FSM_RECOVERY_WAIT
} modem_fsm_state_t;

extern struct ring_buf modem_rx_ring;

extern volatile uint8_t modem_net_lost;
extern volatile uint8_t modem_rf_collapse;

void Modem_EventPush(modem_event_t evt);
modem_event_t Modem_EventPull(void);
void Modem_EventDrain(void);

void Modem_RingPush(const uint8_t *data, uint16_t len);
uint8_t Modem_RingContains(const char *needle);
uint8_t Modem_RingConsume(const char *needle);
int Modem_RingFindByte(char c);
void Modem_RingDrop(uint16_t n);
void Modem_RingFlush(void);

uint8_t Modem_ExtractLine(char *out, uint16_t out_len);
void Modem_ParseResponses(void);

uint8_t Modem_SendAt(const char *cmd);
uint8_t Modem_WaitEvent(modem_event_t want, uint32_t ms);
uint8_t Modem_WaitOkOrErr(uint32_t ms);
uint8_t Modem_WaitPrompt(uint32_t ms);
uint8_t Modem_WaitSendOk(uint32_t ms);
void Modem_AbortQisend(void);
uint8_t Modem_EnsureCommandMode(void);

void Modem_RxPump(void);
void Modem_SnapshotRing(char *out, uint16_t out_len);
void Modem_UartBringup(void);

uint8_t Modem_ProbeOn(void);
uint8_t Modem_PowerOnVerified(void);
void Modem_EnsurePoweredDown(void);

uint8_t Modem_InitModemConfig(void);
void Modem_QueryRfStatus(void);
uint8_t Modem_WaitRfReady(uint32_t ms);
void Modem_SampleVbat(void);
void Modem_QueryAttachDiag(void);
uint8_t Modem_QuerySocketUp(void);
uint8_t Modem_SyncReopenSocket(void);
uint8_t Modem_EnsureSocketUp(void);
uint8_t Modem_BringLinkUp(void);
uint8_t Modem_UdpSendNow(void);

void Modem_InitPowerPins(void);
void Modem_HwReset(void);
void Modem_SetPendingPayload(const uint8_t *buf, uint16_t len);
uint8_t Modem_IsUartBusy(void);

void Modem_UpdateLive(void);

#endif
```
